# psoc4hvpaspm10 register map
Vendor: Infineon Technologies; Series: PSOC4HVPASPM10; File version: 1.0
CPU: CM0PLUS r0p1, little endian, MPU, no FPU, VTOR, 2 interrupt priority bits, 32 interrupts
Registers are 32-bit, read-write, reset 0x0 unless marked. A register's access mark holds for its fields unless they carry their own. Offsets are from the block's base; [hi:lo] are bit positions; {n}, {i} and the like mark numbered series; 'fields as' and 'values as' point back to an identical list; <NAME> marks a mode.

## CPUSS — CPU Subsystem
Base 0x40100000
0x00 CONFIG — Configuration register
  [0] VECT_IN_RAM — 0': Vector Table is located at 0x0000:0000 in flash '1': Vector Table is located at 0x2000:0000 in SRAM Note that vectors for RESET and FAULT are always fetched from ROM. Value in flash/RAM is ignored for these vectors.
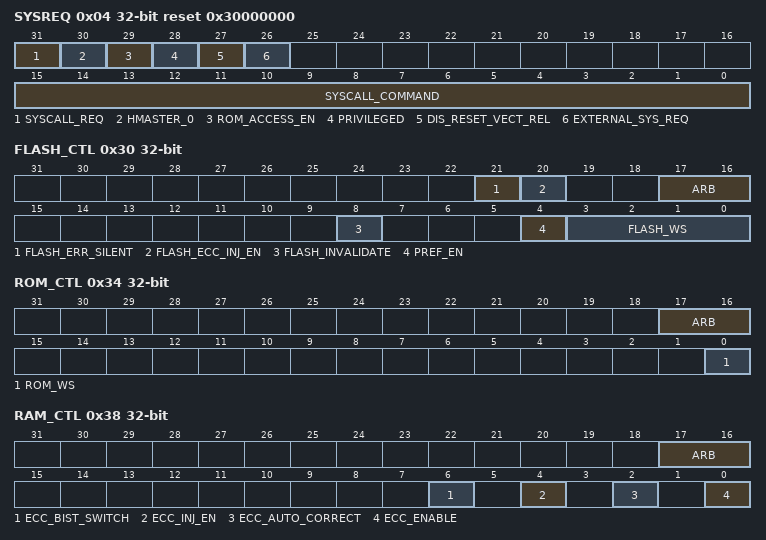
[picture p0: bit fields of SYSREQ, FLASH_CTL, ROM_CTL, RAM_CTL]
0x04 SYSREQ reset 0x30000000 — SYSCALL control register
  [31] SYSCALL_REQ — CPU/DAP writes a '1' to this field to request a SystemCall. The HMASTER_0 field indicates the source of the write access. Setting this field to '1' immediate results in a NMI. The SystemCall NMI interrupt handler sets this field to '0' after servicing the request.
  [30] HMASTER_0 ro — Indicates the source of the write access to the SYSREQ register. '0': CPU write access. '1': DAP write access. For a SW write to the SYSREQ register, the HW will update this field based on the value of SYSCALL_REQ. SYSCALL_REQ = 0 : the current source of write access is captured. SYSCALL_REQ = 1 : the previous value (captured when SYSCALL_REQ was 0), is retained/maintained until the next SW write to this register.
  [29] ROM_ACCESS_EN ro — Indicates that executing from Boot ROM is enabled. HW sets this field to '1', on reset or when the SystemCall NMI vector is fetched from Boot ROM. HW sets this field to '0', when the CPU is NOT executing from either Boot or System ROM. This bit is used for debug purposes only.
  [28] PRIVILEGED — Indicates whether the system is in privileged ('1') or user mode ('0'). Only CPU SW executing from ROM can set this field to '1' when ROM_ACCESS_EN is '1' (the CPU is executing a SystemCall NMI interrupt handler). Any other write to this field sets is to '0'. This field is used as the AHB-Lite hprot[1] signal to implement Infineon proprietary user/privileged modes. These modes are used to enable/disable access to specific MMIO registers and memory regions.
  [27] DIS_RESET_VECT_REL — Disable Reset Vector fetch relocation: '0': CPU accesses to locations 0x0000:0000 - 0x0000:0007 are redirected to ROM. '1': CPU accesses to locations 0x0000:0000 - 0x0000:0007 are made to flash. Note that this field defaults to '0' on reset, ensuring actual reset vector fetches are always made to ROM. Note that this field does not affect DAP accesses. Flash DfT routines may set this bit to '1' to enable uninhibited read-back of programmed data in the first flash page.
  [26] EXTERNAL_SYS_REQ write-1-clears — External HW SYS REQ. This bit is set by HW to cause a SYSCALL to BOOTROM. This bit may only be cleared by SW. When this bit is set, the SYSCALL_COMMAND, PRIVILEDGED, HMASTER0, and SYSCALL_ARG content are invalid.
  [15:0] SYSCALL_COMMAND — Opcode of the system call being requested.
0x08 SYSARG — SYSARG control register
  [31:0] SYSCALL_ARG — Argument to System Call specified in SYSREQ. Semantics of argument depends on system call made. Typically a pointer to a parameter block.
0x20 INT_SEL — Interrupt multiplexer select register
  [31:0] DSI — Specifies interrupt source: '0': Fixed Function. '1': DSI. When changing the source of a specific interrupt, it is advised to temporarily disable the interrupt using the CM0 NVIC's CLRENA and SETENA interrupt enable clear and set registers to prevent a spurious interrupt activation. In addition, the CM0 NVIC's CLRPEND interrupt pending clear register should be used clear a pending interrupt before re-enabling the interrupt.
0x24 INT_MODE — DSI interrupt pulse mode register
  [31:0] DSI_INT_PULSE — Specifies DSI interrupt format: '0': level sensitive; i.e. no pulse generator. '1': pulse generator on rising edge.
0x28 NMI_MODE — DSI NMI pulse mode register
  [0] DSI_NMI_PULSE — Specifies DSI NMI format: '0': level sensitive; i.e. no pulse generator. '1': pulse generator on rising edge.
0x30 FLASH_CTL — FLASH control register
  [21] FLASH_ERR_SILENT
  [20] FLASH_ECC_INJ_EN
  [17:16] ARB
  [8] FLASH_INVALIDATE
  [4] PREF_EN
  [3:0] FLASH_WS — For Flash With ECC the number of wait states (WS): WS = 3 for SYSCLK <= FMAX WS = 2 for SYSCLK <= 3/4 * FMAX WS = 1 for SYSCLK <= 1/2 * FMAX WS = 0 for SYSCLK <= 1/4 * FMAX 4-15 : Future Use - To be used, if 3 Wait State is not sufficient.
0x34 ROM_CTL — ROM control register
  [17:16] ARB
  [0] ROM_WS — Amount of ROM wait states: '0': 0 wait states. Use this setting for newer, faster ROM design. Use this setting for older, slower ROM design and frequencies in the range [0, 24] MHz. '1': 1 wait state. Use this setting for older, slower ROM design and frequencies in the range <24, 48] MHz. Should always be set to 0.
0x38 RAM_CTL — RAM control register
  [17:16] ARB — Arbitration Policy: '0': CPU has priority '1': DW/DMA has priority '2': Roundrobin '3': Roundrobin - sticky
  [6] ECC_BIST_SWITCH — ECC_BIST_SWITCH: Substitutes Syndrome bits for normal data path during BIST testing. Data bits 31:25 on the SRAM data path both to and from the SRAM are replaced with the SRAM Syndrome data bits 38:32 during BIST testing when this bit is set to 1. '0': Source normal datapath to BIST bus '1': Source Syndrome bits to BIST bus
  [4] ECC_INJ_EN — Enable error injection. 0: Syndrome is source from ECC Syndrome hardware. 1: ECC_TEST.SYND_DATA is used when a full 32-bit write is done to the ECC_TEST.WORD_ADDR word address of SRAM0.
  [2] ECC_AUTO_CORRECT — HW ECC autocorrect functionality: '0': Disabled. '1': Enabled. HW automatically writes back SRAM with corrected data when a recoverable ECC error is detected.
  [0] ECC_ENABLE — Enable ECC operation: '0': ECC Disabled - ECC is not generated/checked '1': ECC Enabled - ECC is generated/checked
0x3C DMAC_CTL — DMA controller register
  [17:16] ARB — Arbitration policy: 0: CPU has priority 1: DW/DMA has priority 2: Roundrobin 3: Roundrobin - sticky
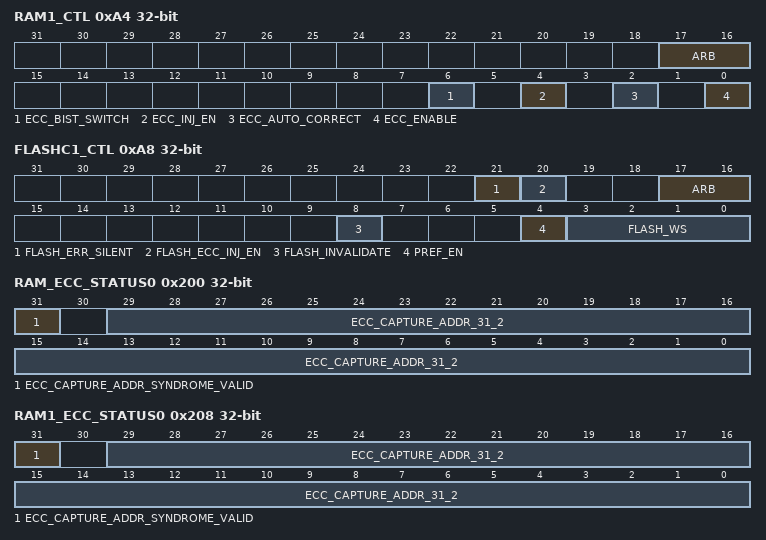
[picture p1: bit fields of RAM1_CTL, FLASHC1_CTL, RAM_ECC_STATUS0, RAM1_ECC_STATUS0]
0xA4 RAM1_CTL — RAM 1 control register
  [17:16] ARB — Arbitration policy: 0: CPU has priority 1: DW/DMA has priority 2: Roundrobin 3: Roundrobin - sticky
  [6] ECC_BIST_SWITCH — ECC_BIST_SWITCH: Substitutes Syndrome bits for normal data path during BIST testing. Data bits 31:25 on the SRAM data path both to and from the SRAM are replaced with the SRAM Syndrome data bits 38:32 during BIST testing when this bit is set to 1. '0': Source normal datapath to BIST bus '1': Source Syndrome bits to BIST bus
  [4] ECC_INJ_EN — Enable error injection. 0: Syndrome is source from ECC Syndrome hardware. 1: ECC_TEST.SYND_DATA is used when a full 32-bit write is done to the ECC_TEST.WORD_ADDR word address of SRAM1.
  [2] ECC_AUTO_CORRECT — HW ECC autocorrect functionality: '0': Disabled. '1': Enabled. HW automatically writes back SRAM with corrected data when a recoverable ECC error is detected.
  [0] ECC_ENABLE — Enable ECC operation: '0': ECC Disabled - ECC is not generated/checked '1': ECC Enabled - ECC is generated/checked
0xA8 FLASHC1_CTL — FLASH Control1 control register
  [21] FLASH_ERR_SILENT — Specifies bus transfer behavior for a non-recoverable error on the FLASH macro main interface (either a non-correctable ECC error, a FLASH macro main interface internal error, a FLASH macro main interface memory hole access, a M0S8 protection violation error): 0: Bus transfer has a bus error. 1: Bus transfer does NOT have a bus error; i.e. the error is 'silent' In either case, a Zero value is returned. This field is ONLY used by CPU bus transfers. Non-CPU bus transfers always have a bus transfer with a bus error, in case of a non-recoverable error
  [20] FLASH_ECC_INJ_EN — Enable error injection for FLASH main interface. When'1', the parity (ECC_CTL.PARITY[7:0]) is used for a load from the ECC_CTL.WORD_ADDR[23:0] word address.
  [17:16] ARB — Arbitration policy: 0: CPU has priority 1: DW/DMA has priority 2: Roundrobin 3: Roundrobin - sticky
  [8] FLASH_INVALIDATE — 1': Invalidates the content of the flash controller's buffers.
  [4] PREF_EN — Prefetch enable: '0': disabled. This is a desirable setting when FLASH_WS is 0 or when predictable execution behavior is required. '1': enabled.
  [3:0] FLASH_WS — Amount of ROM wait states: For Flash (without ECC). 0: 0 wait states (fast flash: [0, 24] MHz system frequency, slow flash: [0, 16] MHz system frequency) 1: 1 wait state (fast flash: [24, 48] MHz system frequency, slow flash: [16, 32] MHz system frequency) 2: 2 wait states (slow flash: [32, 48] MHz system frequency) 3-15 : Future Use. For Flash With ECC. 0: 0 wait states ([0, 12] MHz system frequency) 1: 1 wait state ([12, 24] MHz system frequency) 2: 2 wait states (24,36] MHz system frequency) 3: 3 wait states ([36,48] MHz System Frequency) 4-15 : Future Use - To be used, if 3 Wait State is not sufficient.
0xAC FAULT_CTL — Fault Control Register
  fields as DMAC_CTL
0xB0 MTB_CTL — MTB control register
  [0] CPU_HALT_TSTOP_EN — 1': Enable CPU Halt to stop MTB trace. (HALTED output of CM0+ can stop the trace when high/'1') '0': HALTED output of CM0+ can not strop trace.
0xC4 DAP_CTL ro reset not defined — SWD DP Instance ID
  [3:0] INSTANCE_ID — Specifies the SWD DP Instance ID This is used with the SWD Multi-Drop feature to uniquely identify a chip.
0xD0 RAM_STATUS ro reset 0x1 — RAM Controller 0 Status
  [0] WB_EMPTY — Write buffer empty. This information is used when entering DeepSleep power mode: WB_EMPTY must be '1' before a transition to system DeepSleep power mode. '0': Write buffer NOT empty. '1': Write buffer empty. Note: the SRAM controller write buffer is only used when ECC checking is enabled. (RAMi_CTL.ECC_EN is '1').
0xD4 RAM1_STATUS ro reset 0x1 — RAM Controller 1 Status
  fields as RAM_STATUS
0xE0 BOOT_RESULT_0 reset 0x1 — Boot Result Register 0
  [31:0] BOOT_RESULT — Record details of Boot Process.
0xE4 BOOT_RESULT_1 reset 0x1 — Boot Result Register 1
  [31:0] BOOT_RESULT — Record details of Boot Process.
{0x100+4i} SL_CTL[{i}] (i=0..23) — Slave control register
  [17:16] ARB — Arbitration policy: 0: CPU priority 1: DMA priority 2: Roundrobin 3: Roundrobin - sticky
0x200 RAM_ECC_STATUS0 (reset mask 0x80000000)
  [31] ECC_CAPTURE_ADDR_SYNDROME_VALID write-1-clears — ECC Capture address and Syndrome valid. 0: ECC_CAPTURE_ADDR_31_2 not valid 1: ECC_CAPTURE_ADDR_31_2 valid - SW writes a 1 to clear
  [29:0] ECC_CAPTURE_ADDR_31_2 ro — Snapshot of CPUSS Address which caused the first correctable/un-correctable error interrupt. When first correctable/un-correctable error interrupt is generated, ECC_CAPTURE_ADDR_SYNDROME_VALID is transitioned from 0 to 1 , and this registered captures the first error address. The register only captures bits 31-2 of the address.
0x204 RAM_ECC_STATUS1 ro reset not defined
  [6:0] ECC_CAPTURE_SYNDROME — Snapshot of CPUSS Syndrome which caused the first correctable/un-correctable error interrupt. When first correctable/un-correctable error interrupt is generated, ECC_CAPTURE_ADDR_SYNDROME_VALID is transitioned from 0 to 1 , and this registered captures the first Syndrome corresponding to the Error.
0x208 RAM1_ECC_STATUS0 (reset mask 0x80000000)
  fields as RAM_ECC_STATUS0
0x20C RAM1_ECC_STATUS1 ro reset not defined
  fields as RAM_ECC_STATUS1
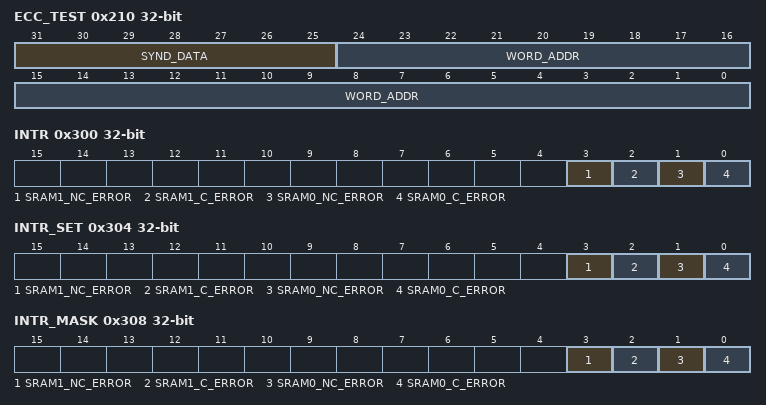
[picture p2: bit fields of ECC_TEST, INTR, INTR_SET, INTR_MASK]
0x210 ECC_TEST
  [31:25] SYND_DATA — ECC syndrome to use for error injection at address WORD_ADDR.
  [24:0] WORD_ADDR — Specifies the word address where an error will be injected. - For SRAMs, the word address WORD_ADDR[24:0] is the device address A[26:2]. On a write transfer to this SRAM address and when the corresponding RAM_CTL.ECC_INJ_EN or RAM1_CTL.ECC_INJ_EN bit is '1', the parity (SYND_DATA[6:0]) is injected into the corresponding SRAM location.
0x300 INTR — Interrupt register
  [3] SRAM1_NC_ERROR write-1-clears — Uncorrectable ECC Error For SRAM1 - interrupt signaled on interrupt_sram1_nc_ecc
  [2] SRAM1_C_ERROR write-1-clears — Correctable ECC Error For SRAM1 - interrupt signaled on interrupt_sram1_c_ecc
  [1] SRAM0_NC_ERROR write-1-clears — Uncorrectable ECC Error For SRAM - interrupt signaled on interrupt_sram_nc_ecc
  [0] SRAM0_C_ERROR write-1-clears — Correctable ECC Error For SRAM - interrupt signaled on interrupt_sram_nc_ecc
0x304 INTR_SET — Interrupt set register
  [3] SRAM1_NC_ERROR write-1-sets — SW writes a '1' to this field to set the corresponding field in interrupt request register.
  [2] SRAM1_C_ERROR write-1-sets — SW writes a '1' to this field to set the corresponding field in interrupt request register.
  [1] SRAM0_NC_ERROR write-1-sets — SW writes a '1' to this field to set the corresponding field in interrupt request register.
  [0] SRAM0_C_ERROR write-1-sets — SW writes a '1' to this field to set the corresponding field in interrupt request register.
0x308 INTR_MASK — Interrupt mask register
  [3] SRAM1_NC_ERROR — Mask bit for corresponding field in interrupt request register.
  [2] SRAM1_C_ERROR — Mask bit for corresponding field in interrupt request register.
  [1] SRAM0_NC_ERROR — Mask bit for corresponding field in interrupt request register.
  [0] SRAM0_C_ERROR — Mask bit for corresponding field in interrupt request register.
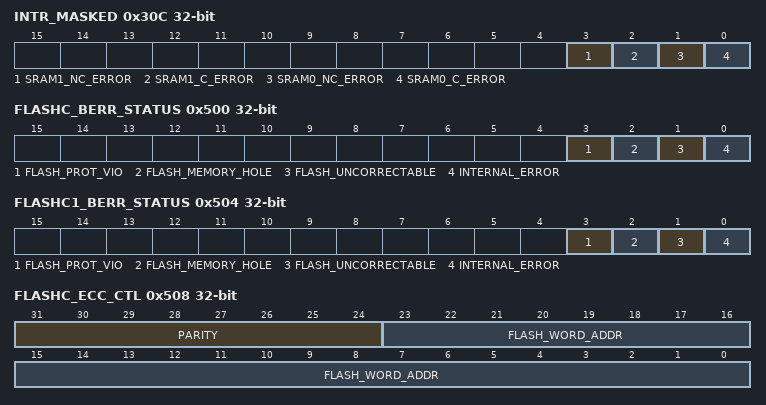
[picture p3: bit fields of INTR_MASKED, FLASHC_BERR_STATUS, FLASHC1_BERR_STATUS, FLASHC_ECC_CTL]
0x30C INTR_MASKED ro — Interrupt masked register
  [3] SRAM1_NC_ERROR — Logical and of corresponding request and mask bits.
  [2] SRAM1_C_ERROR — Logical and of corresponding request and mask bits.
  [1] SRAM0_NC_ERROR — Logical and of corresponding request and mask bits.
  [0] SRAM0_C_ERROR — Logical and of corresponding request and mask bits.
0x400 EXT_MS_CTL — External master control register
  [17:16] ARB — Arbitration policy: 0: EXTM0/DMAC has priority 1: EXTM1 has priority 2: Roundrobin 3: Roundrobin - sticky
0x500 FLASHC_BERR_STATUS — Flash Bus Error Status
  [3] FLASH_PROT_VIO write-1-clears — A protection violation occurred in Flash Controller. SW clears this field to '0'. HW sets this field to '1' on a protection violation occurred in Flash Controllers. Typically, SW reads this field after a code section to detect the occurrence of an error. Note: this field is independent of FLASH_CTL.FLASH_ERR_SILENT.
  [2] FLASH_MEMORY_HOLE write-1-clears
  [1] FLASH_UNCORRECTABLE write-1-clears
  [0] INTERNAL_ERROR write-1-clears
0x504 FLASHC1_BERR_STATUS — Flash 1 Bus Error Status
  [3] FLASH_PROT_VIO write-1-clears — See the Explanation for FLASHC_BERR_STATUS
  [2] FLASH_MEMORY_HOLE write-1-clears — See the Explanation for FLASHC_BERR_STATUS
  [1] FLASH_UNCORRECTABLE write-1-clears — See the Explanation for FLASHC_BERR_STATUS
  [0] INTERNAL_ERROR write-1-clears — See the Explanation for FLASHC_BERR_STATUS
0x508 FLASHC_ECC_CTL — Flash ECC Control
  [31:24] PARITY — ECC parity to use for ECC error injection at address WORD_ADDR. - For FLASH interface ECC, the 8-bit parity PARITY[7:0] is for a 64-bit word.
  [23:0] FLASH_WORD_ADDR — Specifies the word address where an error will be injected. - For FLASH interface ECC, the word address WORD_ADDR[23:0] is device address A[26:3]. On a FLASH main interface read and when FLASH_CTL.MAIN_ECC_INJ_EN bit is '1', the parity (PARITY[7:0]) replaces the FLASH macro parity (FLASH main interface read path is manipulated).
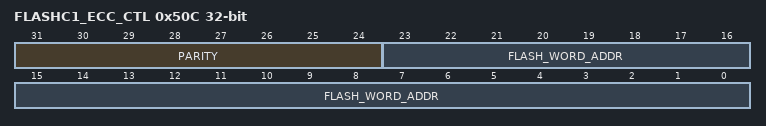
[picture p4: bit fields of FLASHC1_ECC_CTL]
0x50C FLASHC1_ECC_CTL — Flash 1 ECC Control
  [31:24] PARITY — See the Explanation for FLASHC_ECC_CTL
  [23:0] FLASH_WORD_ADDR — See the Explanation for FLASHC_ECC_CTL
